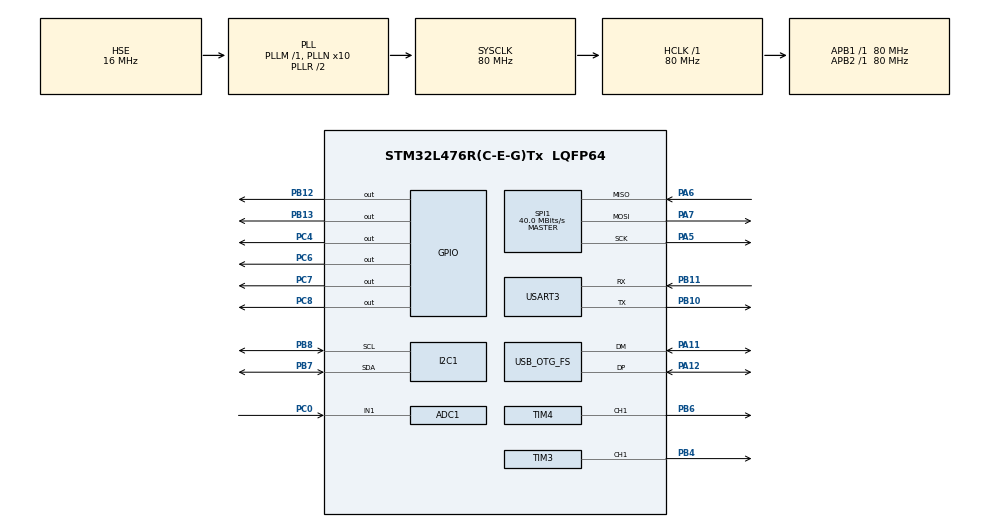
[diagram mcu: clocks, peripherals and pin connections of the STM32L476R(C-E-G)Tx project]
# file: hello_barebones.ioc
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Mcu.Family=STM32L4
PA6.Mode=Full_Duplex_Master
USB_DEVICE.CLASS_NAME_FS=CDC
RCC.CortexFreq_Value=80000000
SPI1.VirtualType=VM_MASTER
PB10.Mode=Asynchronous
PH0-OSC_IN\ (PH0).Signal=RCC_OSC_IN
ADC1.SamplingTime-6\#ChannelRegularConversion=ADC_SAMPLETIME_2CYCLES_5
PA11.Mode=Device_Only
PB11.Signal=USART3_RX
PB13.Signal=GPIO_Output
RCC.SYSCLKSource=RCC_SYSCLKSOURCE_PLLCLK
ProjectManager.StackSize=0x400
PB3\ (JTDO-TRACESWO).Signal=SYS_JTDO-SWO
USART3.VirtualMode-Asynchronous=VM_ASYNC
PA14\ (JTCK-SWCLK).Signal=SYS_JTCK-SWCLK
PA12.Signal=USB_OTG_FS_DP
SPI1.Direction=SPI_DIRECTION_2LINES
RCC.HCLKFreq_Value=80000000
RCC.APB2TimFreq_Value=80000000
PB6.Signal=S_TIM4_CH1
PC7.Signal=GPIO_Output
SPI1.CalculateBaudRate=40.0 MBits/s
RCC.AHBFreq_Value=80000000
TIM3.Channel-PWM\ Generation1\ CH1=TIM_CHANNEL_1
PH1-OSC_OUT\ (PH1).Mode=HSE-External-Oscillator
RCC.HSE_VALUE=16000000
ADC1.Channel-6\#ChannelRegularConversion=ADC_CHANNEL_1
PB7.Signal=I2C1_SDA
SH.S_TIM3_CH1.0=TIM3_CH1,PWM Generation1 CH1
Mcu.Package=LQFP64
PA6.Signal=SPI1_MISO
NVIC.OTG_FS_IRQn=true\:0\:0\:false\:false\:true\:false\:true
USB_OTG_FS.VirtualMode=Device_Only
SH.ADCx_IN1.0=ADC1_IN1,IN1-Single-Ended
SH.S_TIM4_CH1.0=TIM4_CH1,PWM Generation1 CH1
RCC.APB1TimFreq_Value=80000000
PA13\ (JTMS-SWDIO).Signal=SYS_JTMS-SWDIO
ADC1.Rank-6\#ChannelRegularConversion=1
SPI1.BaudRatePrescaler=SPI_BAUDRATEPRESCALER_2
PH0-OSC_IN\ (PH0).Mode=HSE-External-Oscillator
RCC.PLLSAI1R=RCC_PLLR_DIV4
RCC.PLLSAI1Q=RCC_PLLQ_DIV4
RCC.PLLSAI1N=12
PA5.Mode=Full_Duplex_Master
RCC.MSI_VALUE=4000000
RCC.PLLSourceVirtual=RCC_PLLSOURCE_HSE
TIM4.Channel-PWM\ Generation1\ CH1=TIM_CHANNEL_1
PA14\ (JTCK-SWCLK).Mode=Trace_Asynchronous_SW
PA7.Mode=Full_Duplex_Master
USB_DEVICE.VirtualModeFS=Cdc_FS
PC8.Signal=GPIO_Output
PC4.Signal=GPIO_Output
PC6.Signal=GPIO_Output
PC15-OSC32_OUT\ (PC15).Signal=RCC_OSC32_OUT
PA14\ (JTCK-SWCLK).GPIO_Label=TCK
PB3\ (JTDO-TRACESWO).GPIO_Label=SWO
PC0.Signal=ADCx_IN1
PH1-OSC_OUT\ (PH1).Signal=RCC_OSC_OUT
PB11.Mode=Asynchronous
ProjectManager.TargetToolchain=STM32CubeIDE
VP_USB_DEVICE_VS_USB_DEVICE_CDC_FS.Mode=CDC_FS
I2C1.Timing=0x10909CEC
RCC.USBFreq_Value=48000000
RCC.LSE_VALUE=32768
PB10.Signal=USART3_TX
PA5.Signal=SPI1_SCK
board=NUCLEO-L476RG
RCC.VCOOutputFreq_Value=160000000
RCC.APB2Freq_Value=80000000
PA13\ (JTMS-SWDIO).GPIO_Label=TMS
SPI1.Mode=SPI_MODE_MASTER
PB3\ (JTDO-TRACESWO).Mode=Trace_Asynchronous_SW
RCC.ADCFreq_Value=48000000
Mcu.Name=STM32L476R(C-E-G)Tx
ADC1.OffsetNumber-6\#ChannelRegularConversion=ADC_OFFSET_NONE
PA13\ (JTMS-SWDIO).Mode=Trace_Asynchronous_SW
RCC.SYSCLKFreq_VALUE=80000000
ADC1.master=1
PA12.Mode=Device_Only
PC14-OSC32_IN\ (PC14).Signal=RCC_OSC32_IN
PB7.Mode=I2C
PA11.Signal=USB_OTG_FS_DM
ProjectManager.HeapSize=0x200
RCC.HSI_VALUE=16000000
NVIC.PriorityGroup=NVIC_PRIORITYGROUP_4
ADC1.NbrOfConversionFlag=1
RCC.PLLN=10
PB8.Mode=I2C
PB8.Signal=I2C1_SCL
RCC.APB1Freq_Value=80000000
USB_DEVICE.VirtualMode=Cdc
PB12.Signal=GPIO_Output
PA7.Signal=SPI1_MOSI
PB4\ (NJTRST).Signal=S_TIM3_CH1

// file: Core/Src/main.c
/* USER CODE BEGIN Header */
/**
  ******************************************************************************
  * @file           : main.c
  * @brief          : Main program body
  ******************************************************************************
  * @attention
  *
  * <h2><center>&copy; Copyright (c) 2021 STMicroelectronics.
  * All rights reserved.</center></h2>
  *
  * This software component is licensed by ST under BSD 3-Clause license,
  * the "License"; You may not use this file except in compliance with the
  * License. You may obtain a copy of the License at:
  *                        opensource.org/licenses/BSD-3-Clause
  *
  ******************************************************************************
  */
/* USER CODE END Header */
#include "main.h"
#include "usb_device.h"

/* USER CODE BEGIN Includes */
#include <stdio.h>
/* USER CODE END Includes */

/* USER CODE BEGIN PD */
#ifdef __GNUC__
#define PUTCHAR_PROTOTYPE int __io_putchar(int ch)
#else
#define PUTCHAR_PROTOTYPE int fputc(int ch, FILE *f)
#endif /* __GNUC__*/

/* USER CODE END PD */

ADC_HandleTypeDef hadc1;

I2C_HandleTypeDef hi2c1;

SPI_HandleTypeDef hspi1;

TIM_HandleTypeDef htim3;
TIM_HandleTypeDef htim4;

UART_HandleTypeDef huart3;

void SystemClock_Config(void);
static void MX_GPIO_Init(void);
static void MX_I2C1_Init(void);
static void MX_USART3_UART_Init(void);
static void MX_SPI1_Init(void);
static void MX_TIM3_Init(void);
static void MX_ADC1_Init(void);
static void MX_TIM4_Init(void);

/* USER CODE BEGIN 0 */
PUTCHAR_PROTOTYPE
{
	//HAL_UART_Transmit(&huart2, (uint8_t *)&ch, 1, pdMS_TO_TICKS(100));
	return ch;
}

/* USER CODE END 0 */

int main(void)
{

  /* MCU Configuration--------------------------------------------------------*/

  /* Reset of all peripherals, Initializes the Flash interface and the Systick. */
  HAL_Init();

  /* Configure the system clock */
  SystemClock_Config();

  /* Initialize all configured peripherals */
  MX_GPIO_Init();
  MX_I2C1_Init();
  MX_USART3_UART_Init();
  MX_USB_DEVICE_Init();
  MX_SPI1_Init();
  MX_TIM3_Init();
  MX_ADC1_Init();
  MX_TIM4_Init();

  /* Infinite loop */
  while (1)
  {

    /* USER CODE BEGIN 3 */
  	HAL_GPIO_TogglePin(GPIOC, GPIO_PIN_6);
  	HAL_GPIO_TogglePin(GPIOC, GPIO_PIN_7);
  	HAL_GPIO_TogglePin(GPIOC, GPIO_PIN_8);

  	HAL_Delay(500);
  }
  /* USER CODE END 3 */
}

void SystemClock_Config(void)
{
  RCC_OscInitTypeDef RCC_OscInitStruct = {0};
  RCC_ClkInitTypeDef RCC_ClkInitStruct = {0};
  RCC_PeriphCLKInitTypeDef PeriphClkInit = {0};

  /** Initializes the RCC Oscillators according to the specified parameters
  * in the RCC_OscInitTypeDef structure.
  */
  RCC_OscInitStruct.OscillatorType = RCC_OSCILLATORTYPE_HSE;
  RCC_OscInitStruct.HSEState = RCC_HSE_ON;
  RCC_OscInitStruct.PLL.PLLState = RCC_PLL_ON;
  RCC_OscInitStruct.PLL.PLLSource = RCC_PLLSOURCE_HSE;
  RCC_OscInitStruct.PLL.PLLM = 1;
  RCC_OscInitStruct.PLL.PLLN = 10;
  RCC_OscInitStruct.PLL.PLLP = RCC_PLLP_DIV7;
  RCC_OscInitStruct.PLL.PLLQ = RCC_PLLQ_DIV2;
  RCC_OscInitStruct.PLL.PLLR = RCC_PLLR_DIV2;
  if (HAL_RCC_OscConfig(&RCC_OscInitStruct) != HAL_OK)
  {
    Error_Handler();
  }
  /** Initializes the CPU, AHB and APB buses clocks
  */
  RCC_ClkInitStruct.ClockType = RCC_CLOCKTYPE_HCLK|RCC_CLOCKTYPE_SYSCLK
                              |RCC_CLOCKTYPE_PCLK1|RCC_CLOCKTYPE_PCLK2;
  RCC_ClkInitStruct.SYSCLKSource = RCC_SYSCLKSOURCE_PLLCLK;
  RCC_ClkInitStruct.AHBCLKDivider = RCC_SYSCLK_DIV1;
  RCC_ClkInitStruct.APB1CLKDivider = RCC_HCLK_DIV1;
  RCC_ClkInitStruct.APB2CLKDivider = RCC_HCLK_DIV1;

  if (HAL_RCC_ClockConfig(&RCC_ClkInitStruct, FLASH_LATENCY_4) != HAL_OK)
  {
    Error_Handler();
  }
  PeriphClkInit.PeriphClockSelection = RCC_PERIPHCLK_USART3|RCC_PERIPHCLK_I2C1
                              |RCC_PERIPHCLK_USB|RCC_PERIPHCLK_ADC;
  PeriphClkInit.Usart3ClockSelection = RCC_USART3CLKSOURCE_PCLK1;
  PeriphClkInit.I2c1ClockSelection = RCC_I2C1CLKSOURCE_PCLK1;
  PeriphClkInit.AdcClockSelection = RCC_ADCCLKSOURCE_PLLSAI1;
  PeriphClkInit.UsbClockSelection = RCC_USBCLKSOURCE_PLLSAI1;
  PeriphClkInit.PLLSAI1.PLLSAI1Source = RCC_PLLSOURCE_HSE;
  PeriphClkInit.PLLSAI1.PLLSAI1M = 1;
  PeriphClkInit.PLLSAI1.PLLSAI1N = 12;
  PeriphClkInit.PLLSAI1.PLLSAI1P = RCC_PLLP_DIV7;
  PeriphClkInit.PLLSAI1.PLLSAI1Q = RCC_PLLQ_DIV4;
  PeriphClkInit.PLLSAI1.PLLSAI1R = RCC_PLLR_DIV4;
  PeriphClkInit.PLLSAI1.PLLSAI1ClockOut = RCC_PLLSAI1_48M2CLK|RCC_PLLSAI1_ADC1CLK;
  if (HAL_RCCEx_PeriphCLKConfig(&PeriphClkInit) != HAL_OK)
  {
    Error_Handler();
  }
  /** Configure the main internal regulator output voltage
  */
  if (HAL_PWREx_ControlVoltageScaling(PWR_REGULATOR_VOLTAGE_SCALE1) != HAL_OK)
  {
    Error_Handler();
  }
}

static void MX_ADC1_Init(void)
{

  ADC_MultiModeTypeDef multimode = {0};
  ADC_ChannelConfTypeDef sConfig = {0};

  /** Common config
  */
  hadc1.Instance = ADC1;
  hadc1.Init.ClockPrescaler = ADC_CLOCK_ASYNC_DIV1;
  hadc1.Init.Resolution = ADC_RESOLUTION_12B;
  hadc1.Init.DataAlign = ADC_DATAALIGN_RIGHT;
  hadc1.Init.ScanConvMode = ADC_SCAN_DISABLE;
  hadc1.Init.EOCSelection = ADC_EOC_SINGLE_CONV;
  hadc1.Init.LowPowerAutoWait = DISABLE;
  hadc1.Init.ContinuousConvMode = DISABLE;
  hadc1.Init.NbrOfConversion = 1;
  hadc1.Init.DiscontinuousConvMode = DISABLE;
  hadc1.Init.ExternalTrigConv = ADC_SOFTWARE_START;
  hadc1.Init.ExternalTrigConvEdge = ADC_EXTERNALTRIGCONVEDGE_NONE;
  hadc1.Init.DMAContinuousRequests = DISABLE;
  hadc1.Init.Overrun = ADC_OVR_DATA_PRESERVED;
  hadc1.Init.OversamplingMode = DISABLE;
  if (HAL_ADC_Init(&hadc1) != HAL_OK)
  {
    Error_Handler();
  }
  /** Configure the ADC multi-mode
  */
  multimode.Mode = ADC_MODE_INDEPENDENT;
  if (HAL_ADCEx_MultiModeConfigChannel(&hadc1, &multimode) != HAL_OK)
  {
    Error_Handler();
  }
  /** Configure Regular Channel
  */
  sConfig.Channel = ADC_CHANNEL_1;
  sConfig.Rank = ADC_REGULAR_RANK_1;
  sConfig.SamplingTime = ADC_SAMPLETIME_2CYCLES_5;
  sConfig.SingleDiff = ADC_SINGLE_ENDED;
  sConfig.OffsetNumber = ADC_OFFSET_NONE;
  sConfig.Offset = 0;
  if (HAL_ADC_ConfigChannel(&hadc1, &sConfig) != HAL_OK)
  {
    Error_Handler();
  }

}

static void MX_I2C1_Init(void)
{

  hi2c1.Instance = I2C1;
  hi2c1.Init.Timing = 0x10909CEC;
  hi2c1.Init.OwnAddress1 = 0;
  hi2c1.Init.AddressingMode = I2C_ADDRESSINGMODE_7BIT;
  hi2c1.Init.DualAddressMode = I2C_DUALADDRESS_DISABLE;
  hi2c1.Init.OwnAddress2 = 0;
  hi2c1.Init.OwnAddress2Masks = I2C_OA2_NOMASK;
  hi2c1.Init.GeneralCallMode = I2C_GENERALCALL_DISABLE;
  hi2c1.Init.NoStretchMode = I2C_NOSTRETCH_DISABLE;
  if (HAL_I2C_Init(&hi2c1) != HAL_OK)
  {
    Error_Handler();
  }
  /** Configure Analogue filter
  */
  if (HAL_I2CEx_ConfigAnalogFilter(&hi2c1, I2C_ANALOGFILTER_ENABLE) != HAL_OK)
  {
    Error_Handler();
  }
  /** Configure Digital filter
  */
  if (HAL_I2CEx_ConfigDigitalFilter(&hi2c1, 0) != HAL_OK)
  {
    Error_Handler();
  }

}

static void MX_SPI1_Init(void)
{

  /* SPI1 parameter configuration*/
  hspi1.Instance = SPI1;
  hspi1.Init.Mode = SPI_MODE_MASTER;
  hspi1.Init.Direction = SPI_DIRECTION_2LINES;
  hspi1.Init.DataSize = SPI_DATASIZE_4BIT;
  hspi1.Init.CLKPolarity = SPI_POLARITY_LOW;
  hspi1.Init.CLKPhase = SPI_PHASE_1EDGE;
  hspi1.Init.NSS = SPI_NSS_SOFT;
  hspi1.Init.BaudRatePrescaler = SPI_BAUDRATEPRESCALER_2;
  hspi1.Init.FirstBit = SPI_FIRSTBIT_MSB;
  hspi1.Init.TIMode = SPI_TIMODE_DISABLE;
  hspi1.Init.CRCCalculation = SPI_CRCCALCULATION_DISABLE;
  hspi1.Init.CRCPolynomial = 7;
  hspi1.Init.CRCLength = SPI_CRC_LENGTH_DATASIZE;
  hspi1.Init.NSSPMode = SPI_NSS_PULSE_ENABLE;
  if (HAL_SPI_Init(&hspi1) != HAL_OK)
  {
    Error_Handler();
  }

}

static void MX_TIM3_Init(void)
{

  TIM_MasterConfigTypeDef sMasterConfig = {0};
  TIM_OC_InitTypeDef sConfigOC = {0};

  htim3.Instance = TIM3;
  htim3.Init.Prescaler = 0;
  htim3.Init.CounterMode = TIM_COUNTERMODE_UP;
  htim3.Init.Period = 65535;
  htim3.Init.ClockDivision = TIM_CLOCKDIVISION_DIV1;
  htim3.Init.AutoReloadPreload = TIM_AUTORELOAD_PRELOAD_DISABLE;
  if (HAL_TIM_PWM_Init(&htim3) != HAL_OK)
  {
    Error_Handler();
  }
  sMasterConfig.MasterOutputTrigger = TIM_TRGO_RESET;
  sMasterConfig.MasterSlaveMode = TIM_MASTERSLAVEMODE_DISABLE;
  if (HAL_TIMEx_MasterConfigSynchronization(&htim3, &sMasterConfig) != HAL_OK)
  {
    Error_Handler();
  }
  sConfigOC.OCMode = TIM_OCMODE_PWM1;
  sConfigOC.Pulse = 0;
  sConfigOC.OCPolarity = TIM_OCPOLARITY_HIGH;
  sConfigOC.OCFastMode = TIM_OCFAST_DISABLE;
  if (HAL_TIM_PWM_ConfigChannel(&htim3, &sConfigOC, TIM_CHANNEL_1) != HAL_OK)
  {
    Error_Handler();
  }
  HAL_TIM_MspPostInit(&htim3);

}

static void MX_TIM4_Init(void)
{

  TIM_MasterConfigTypeDef sMasterConfig = {0};
  TIM_OC_InitTypeDef sConfigOC = {0};

  htim4.Instance = TIM4;
  htim4.Init.Prescaler = 0;
  htim4.Init.CounterMode = TIM_COUNTERMODE_UP;
  htim4.Init.Period = 65535;
  htim4.Init.ClockDivision = TIM_CLOCKDIVISION_DIV1;
  htim4.Init.AutoReloadPreload = TIM_AUTORELOAD_PRELOAD_DISABLE;
  if (HAL_TIM_PWM_Init(&htim4) != HAL_OK)
  {
    Error_Handler();
  }
  sMasterConfig.MasterOutputTrigger = TIM_TRGO_RESET;
  sMasterConfig.MasterSlaveMode = TIM_MASTERSLAVEMODE_DISABLE;
  if (HAL_TIMEx_MasterConfigSynchronization(&htim4, &sMasterConfig) != HAL_OK)
  {
    Error_Handler();
  }
  sConfigOC.OCMode = TIM_OCMODE_PWM1;
  sConfigOC.Pulse = 0;
  sConfigOC.OCPolarity = TIM_OCPOLARITY_HIGH;
  sConfigOC.OCFastMode = TIM_OCFAST_DISABLE;
  if (HAL_TIM_PWM_ConfigChannel(&htim4, &sConfigOC, TIM_CHANNEL_1) != HAL_OK)
  {
    Error_Handler();
  }
  HAL_TIM_MspPostInit(&htim4);

}

static void MX_USART3_UART_Init(void)
{

  huart3.Instance = USART3;
  huart3.Init.BaudRate = 115200;
  huart3.Init.WordLength = UART_WORDLENGTH_8B;
  huart3.Init.StopBits = UART_STOPBITS_1;
  huart3.Init.Parity = UART_PARITY_NONE;
  huart3.Init.Mode = UART_MODE_TX_RX;
  huart3.Init.HwFlowCtl = UART_HWCONTROL_NONE;
  huart3.Init.OverSampling = UART_OVERSAMPLING_16;
  huart3.Init.OneBitSampling = UART_ONE_BIT_SAMPLE_DISABLE;
  huart3.AdvancedInit.AdvFeatureInit = UART_ADVFEATURE_NO_INIT;
  if (HAL_UART_Init(&huart3) != HAL_OK)
  {
    Error_Handler();
  }

}

static void MX_GPIO_Init(void)
{
  GPIO_InitTypeDef GPIO_InitStruct = {0};

  /* GPIO Ports Clock Enable */
  __HAL_RCC_GPIOC_CLK_ENABLE();
  __HAL_RCC_GPIOH_CLK_ENABLE();
  __HAL_RCC_GPIOA_CLK_ENABLE();
  __HAL_RCC_GPIOB_CLK_ENABLE();

  /*Configure GPIO pin Output Level */
  HAL_GPIO_WritePin(GPIOC, GPIO_PIN_4|GPIO_PIN_6|GPIO_PIN_7|GPIO_PIN_8, GPIO_PIN_RESET);

  /*Configure GPIO pin Output Level */
  HAL_GPIO_WritePin(GPIOB, GPIO_PIN_12|GPIO_PIN_13, GPIO_PIN_RESET);

  /*Configure GPIO pins : PC4 PC6 PC7 PC8 */
  GPIO_InitStruct.Pin = GPIO_PIN_4|GPIO_PIN_6|GPIO_PIN_7|GPIO_PIN_8;
  GPIO_InitStruct.Mode = GPIO_MODE_OUTPUT_PP;
  GPIO_InitStruct.Pull = GPIO_NOPULL;
  GPIO_InitStruct.Speed = GPIO_SPEED_FREQ_LOW;
  HAL_GPIO_Init(GPIOC, &GPIO_InitStruct);

  /*Configure GPIO pins : PB12 PB13 */
  GPIO_InitStruct.Pin = GPIO_PIN_12|GPIO_PIN_13;
  GPIO_InitStruct.Mode = GPIO_MODE_OUTPUT_PP;
  GPIO_InitStruct.Pull = GPIO_NOPULL;
  GPIO_InitStruct.Speed = GPIO_SPEED_FREQ_LOW;
  HAL_GPIO_Init(GPIOB, &GPIO_InitStruct);

}

void Error_Handler(void)
{
  __disable_irq();
  while (1)
  {
  }
}

/************************ (C) COPYRIGHT STMicroelectronics *****END OF FILE****/
